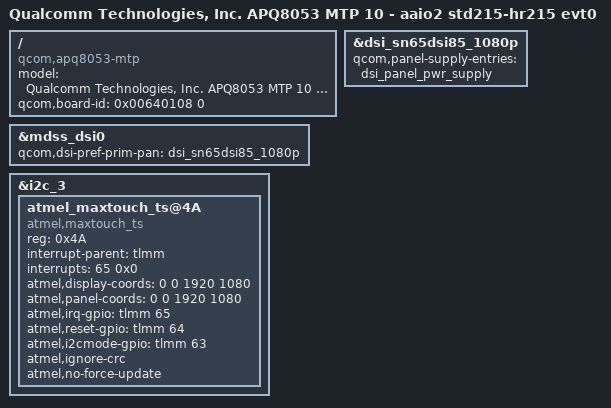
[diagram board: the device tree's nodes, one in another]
/*
 * Copyright (c) 2015-2016, The Linux Foundation. All rights reserved.
 *
 * This program is free software; you can redistribute it and/or modify
 * it under the terms of the GNU General Public License version 2 and
 * only version 2 as published by the Free Software Foundation.
 *
 * This program is distributed in the hope that it will be useful,
 * but WITHOUT ANY WARRANTY; without even the implied warranty of
 * MERCHANTABILITY or FITNESS FOR A PARTICULAR PURPOSE.  See the
 * GNU General Public License for more details.
 */

/dts-v1/;

#include "apq8053.dtsi"
#include "msm8953-mtp.dtsi"
#include "apq8053-oem.dtsi"
#include "apq8053-mtp-lvds-hdmi.dtsi"//Leo Guo add to support all panel in one image
#include "apq8053-mtp-aaio2.dtsi"

/ {
	model = "Qualcomm Technologies, Inc. APQ8053 MTP 10 - aaio2 std215-hr215 evt0";
	compatible = "qcom,apq8053-mtp", "qcom,apq8053", "qcom,mtp";
	qcom,board-id= <0x00640108 0>;
};

&dsi_sn65dsi85_1080p {
	qcom,panel-supply-entries = <&dsi_panel_pwr_supply>;
};

&mdss_dsi0 {
	qcom,dsi-pref-prim-pan = <&dsi_sn65dsi85_1080p>;
};

/* Atmel touch - evt0 wiring: on i2c_3, and no pinctrl */
&i2c_3 {
	atmel_maxtouch_ts@4A {
		compatible = "atmel,maxtouch_ts";
		reg = <0x4A>;
		interrupt-parent = <&tlmm>;
		interrupts = <65 0x0>;
		atmel,display-coords = <0 0 1920 1080>;
		atmel,panel-coords = <0 0 1920 1080>;
		atmel,irq-gpio= <&tlmm 65 0x00>;
		atmel,reset-gpio= <&tlmm 64 0x00>;
		atmel,i2cmode-gpio = <&tlmm 63 0>;
		atmel,ignore-crc;
		atmel,no-force-update;
	};
};
